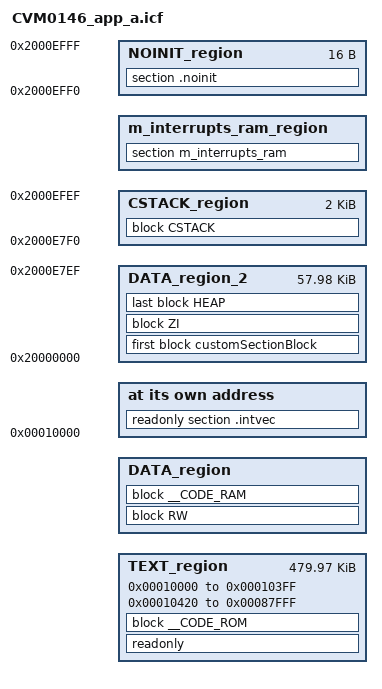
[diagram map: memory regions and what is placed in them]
/*
** Generated by scripts/gen_icf.py -- DO NOT EDIT.
** Source of truth: src/bootif/boot_layout.h
** Regenerate:  python scripts/gen_icf.py
**
** Processor: CVM0146, IAR ANSI C/C++ Compiler for ARM
**
** If symbol __flash_vector_table__=1 is defined at link time the interrupt
** vector will not be copied to RAM (definitive design C15: vector table stays
** in Flash for Boot, App A and App B alike).
**
** SRAM_U top 16 B (0x2000EFF0) is the boot-request no-init zone
** (BOOTIF_RAM_FLAG_* in boot_layout.h). __RAM_END stops right below it so the
** stock startup ECC-init loop never touches the flag - no SDK file is modified.
*/
define symbol __ram_vector_table_size__  =  isdefinedsymbol(__flash_vector_table__) ? 0 : 0x00000400;
define symbol __ram_vector_table_offset__ =  isdefinedsymbol(__flash_vector_table__) ? 0 : 0x000003FF;

/* Flash: CVM0146_app_a */
define symbol m_interrupts_start       = 0x00010000;
define symbol m_interrupts_end         = 0x000103ff;

define symbol m_text_start             = 0x00010420;
define symbol m_text_end               = 0x00087fff;

/* SRAM_L */
define symbol m_interrupts_ram_start   = 0x1FFF0000;
define symbol m_interrupts_ram_end     = 0x1FFF0000 + __ram_vector_table_offset__;

define symbol m_data_start             = m_interrupts_ram_start + __ram_vector_table_size__;
define symbol m_data_end               = 0x1FFFFFFF;

/* SRAM_U - data ends 16 B below chip top; the top zone is the boot-request
** no-init flag (must stay outside the startup ECC-init range [__RAM_START, __RAM_END]) */
define symbol m_data_2_start           = 0x20000000;
define symbol m_data_2_end             = 0x2000eff0 - 1;
define symbol m_data_2_noinit_start    = 0x2000eff0;
define symbol m_data_2_noinit_end      = 0x2000f000 - 1;

/* Sizes */
if (isdefinedsymbol(__stack_size__)) {
  define symbol __size_cstack__        = __stack_size__;
} else {
  define symbol __size_cstack__        = 0x00000800;
}

if (isdefinedsymbol(__heap_size__)) {
  define symbol __size_heap__          = __heap_size__;
} else {
  define symbol __size_heap__          = 0x00000100;
}

define exported symbol __VECTOR_TABLE          = m_interrupts_start;
define exported symbol __VECTOR_RAM            = isdefinedsymbol(__flash_vector_table__) ? m_interrupts_start : m_interrupts_ram_start;
define exported symbol __RAM_VECTOR_TABLE_SIZE = __ram_vector_table_size__;

define exported symbol __RAM_START             = m_interrupts_ram_start;
define exported symbol __RAM_END               = m_data_2_end;

define memory mem with size = 4G;
define region TEXT_region             = mem:[from m_interrupts_start to m_interrupts_end]
                                      | mem:[from m_text_start to m_text_end];
define region DATA_region             = mem:[from m_data_start to m_data_end];
define region DATA_region_2           = mem:[from m_data_2_start to m_data_2_end-__size_cstack__];
define region CSTACK_region           = mem:[from m_data_2_end-__size_cstack__+1 to m_data_2_end];
define region m_interrupts_ram_region = mem:[from m_interrupts_ram_start to m_interrupts_ram_end];
define region NOINIT_region           = mem:[from m_data_2_noinit_start to m_data_2_noinit_end];

define block CSTACK    with alignment = 8, size = __size_cstack__   { };
define block HEAP      with alignment = 8, size = __size_heap__     { };
define block RW        { readwrite };
define block ZI        { zi };

define block customSectionBlock { section .customSection };

define block __CODE_ROM   { section .textrw_init };
define block __CODE_RAM   { section .textrw  };

initialize manually       { section .textrw };
initialize manually       { section .bss };
initialize manually       { section .customSection };
initialize manually       { section .data };
initialize manually       { section __DLIB_PERTHREAD };
do not initialize         { section .noinit, section .bss, section .data, section __DLIB_PERTHREAD, section .customSection };

place at address mem: m_interrupts_start    { readonly section .intvec };
place in TEXT_region                        { readonly };
place in TEXT_region                        { block __CODE_ROM };
place in DATA_region                        { block RW };
place in DATA_region                        { block __CODE_RAM };
place in DATA_region_2                      { first block customSectionBlock };
place in DATA_region_2                      { block ZI };
place in DATA_region_2                      { last block HEAP };
place in CSTACK_region                      { block CSTACK };
place in m_interrupts_ram_region            { section m_interrupts_ram };
place in NOINIT_region                      { section .noinit };
